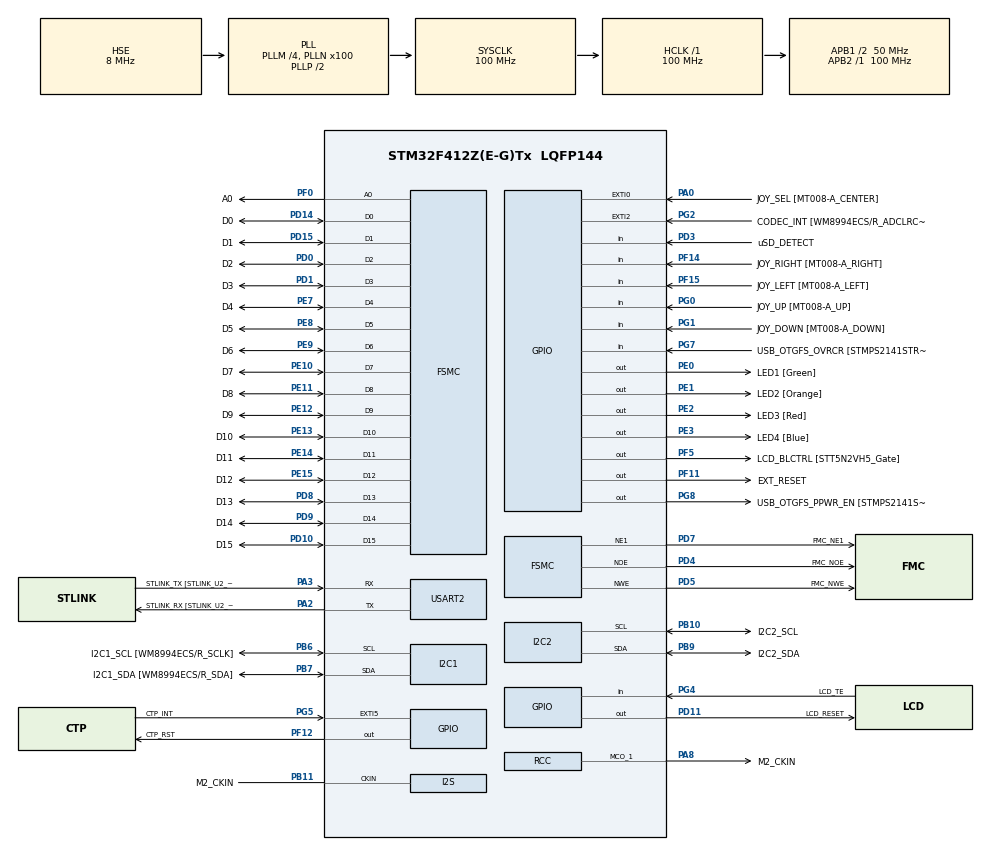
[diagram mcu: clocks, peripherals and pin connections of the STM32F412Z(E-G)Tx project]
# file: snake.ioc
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Mcu.Family=STM32F4
Mcu.Name=STM32F412Z(E-G)Tx
Mcu.Package=LQFP144
NVIC.PriorityGroup=NVIC_PRIORITYGROUP_4
NVIC.TIM6_IRQn=true\:0\:0\:false\:false\:true\:true\:true\:true
PA0.GPIO_Label=JOY_SEL [MT008-A_CENTER]
PA0.Signal=GPXTI0
PA10.GPIO_Label=USB_OTGFS_ID
PA10.Signal=USB_OTG_FS_ID
PA11.GPIO_Label=USB_OTGFS_DM
PA11.Signal=USB_OTG_FS_DM
PA13.GPIO_Label=SWDIO
PA13.Mode=Serial_Wire
PA13.Signal=SYS_JTMS-SWDIO
PA14.GPIO_Label=SWCLK
PA14.Mode=Serial_Wire
PA14.Signal=SYS_JTCK-SWCLK
PA2.GPIO_Label=STLINK_RX [STLINK_U2_RX]
PA2.Mode=Asynchronous
PA2.Signal=USART2_TX
PA3.GPIO_Label=STLINK_TX [STLINK_U2_TX]
PA3.Mode=Asynchronous
PA3.Signal=USART2_RX
PA4.GPIO_Label=CODEC_I2S3_WS [WM8994ECS/R_LRCLK1]
PA4.Signal=I2S3_WS
PA8.GPIO_Label=M2_CKIN
PA8.Mode=Clock-out-1
PA8.Signal=RCC_MCO_1
PA9.GPIO_Label=USB_OTGFS_VBUS
PA9.Signal=USB_OTG_FS_VBUS
PB1.GPIO_Label=DFSDM_DATIN0 [MP34DT01TR_DOUT]
PB1.Signal=S_DATAIN0DFSDM1
PB10.GPIO_Label=I2C2_SCL
PB10.GPIO_Pu=GPIO_PULLUP
PB10.Mode=I2C
PB10.Signal=I2C2_SCL
PB11.GPIO_Label=M2_CKIN
PB11.Mode=Audio_ClockIn
PB11.Signal=I2S_CKIN
PB12.GPIO_Label=CODEC_I2S3_SCK [WM8994ECS/R_BCLK1]
PB12.Signal=I2S3_CK
PB2.GPIO_Label=QSPI_CLK [N25Q128A13EF840F_C]
PB2.Signal=QUADSPI_CLK
PB3.GPIO_Label=SWO
PB3.Signal=SYS_JTDO-SWO
PB4.GPIO_Label=CODEC_I2S3ext_SD [WM8994ECS/R_ACDAT1]
PB4.Signal=I2S3_ext_SD
PB5.GPIO_Label=CODEC_I2S3_SD [WM8994ECS/R_DACDAT1]
PB5.Signal=I2S3_SD
PB6.GPIO_Label=I2C1_SCL [WM8994ECS/R_SCLK]
PB6.GPIO_Pu=GPIO_PULLUP
PB6.Mode=I2C
PB6.Signal=I2C1_SCL
PB7.GPIO_Label=I2C1_SDA [WM8994ECS/R_SDA]
PB7.GPIO_Pu=GPIO_PULLUP
PB7.Mode=I2C
PB7.Signal=I2C1_SDA
PB9.GPIO_Label=I2C2_SDA
PB9.GPIO_Pu=GPIO_PULLUP
PB9.Mode=I2C
PB9.Signal=I2C2_SDA
PC10.GPIO_Label=uSD_D2
PC10.Signal=SDIO_D2
PC11.GPIO_Label=uSD_D3
PC11.Signal=SDIO_D3
PC12.GPIO_Label=uSD_CLK
PC12.Signal=SDIO_CK
PC14-OSC32_IN.Mode=LSE-External-Oscillator
PC14-OSC32_IN.Signal=RCC_OSC32_IN
PC15-OSC32_OUT.Mode=LSE-External-Oscillator
PC15-OSC32_OUT.Signal=RCC_OSC32_OUT
PC2.GPIO_Label=DFSDM_CKOUT [MP34DT01TR_CLK]
PC2.Signal=S_CKOUTDFSDM1
PC7.GPIO_Label=CODEC_I2S3_MCK [WM8994ECS/R_MCLK1]
PC7.Signal=I2S3_MCK
PC8.GPIO_Label=uSD_D0
PC8.Signal=SDIO_D0
PC9.GPIO_Label=uSD_D1
PC9.Signal=SDIO_D1
PD0.GPIO_Label=D2
PD0.Signal=FSMC_D2_DA2
PD1.GPIO_Label=D3
PD1.Signal=FSMC_D3_DA3
PD10.GPIO_Label=D15
PD10.Signal=FSMC_D15_DA15
PD11.GPIO_Label=LCD_RESET
PD11.Signal=GPIO_Output
PD14.GPIO_Label=D0
PD14.Signal=FSMC_D0_DA0
PD15.GPIO_Label=D1
PD15.Signal=FSMC_D1_DA1
PD2.GPIO_Label=uSD_CMD
PD2.Signal=SDIO_CMD
PD3.GPIO_Label=uSD_DETECT
PD3.Signal=GPIO_Input
PD4.GPIO_Label=FMC_NOE
PD4.Signal=FSMC_NOE
PD5.GPIO_Label=FMC_NWE
PD5.Signal=FSMC_NWE
PD7.GPIO_Label=FMC_NE1
PD7.Mode=NorPsramChipSelect1_1
PD7.Signal=FSMC_NE1
PD8.GPIO_Label=D13
PD8.Signal=FSMC_D13_DA13
PD9.GPIO_Label=D14
PD9.Signal=FSMC_D14_DA14
PE0.GPIO_Label=LED1 [Green]
PE0.GPIO_ModeDefaultOutputPP=GPIO_MODE_OUTPUT_OD
PE0.Signal=GPIO_Output
PE1.GPIO_Label=LED2 [Orange]
PE1.GPIO_ModeDefaultOutputPP=GPIO_MODE_OUTPUT_OD
PE1.Signal=GPIO_Output
PE10.GPIO_Label=D7
PE10.Signal=FSMC_D7_DA7
PE11.GPIO_Label=D8
PE11.Signal=FSMC_D8_DA8
PE12.GPIO_Label=D9
PE12.Signal=FSMC_D9_DA9
PE13.GPIO_Label=D10
PE13.Signal=FSMC_D10_DA10
PE14.GPIO_Label=D11
PE14.Signal=FSMC_D11_DA11
PE15.GPIO_Label=D12
PE15.Signal=FSMC_D12_DA12
PE2.GPIO_Label=LED3 [Red]
PE2.GPIO_ModeDefaultOutputPP=GPIO_MODE_OUTPUT_OD
PE2.Signal=GPIO_Output
PE3.GPIO_Label=LED4 [Blue]
PE3.GPIO_ModeDefaultOutputPP=GPIO_MODE_OUTPUT_OD
PE3.Signal=GPIO_Output
PE4.GPIO_Label=DFSDM_DATIN3 [MP23DB01MM_DOUT]
PE4.Signal=S_DATAIN3DFSDM1
PE7.GPIO_Label=D4
PE7.Signal=FSMC_D4_DA4
PE8.GPIO_Label=D5
PE8.Signal=FSMC_D5_DA5
PE9.GPIO_Label=D6
PE9.Signal=FSMC_D6_DA6
PF0.GPIO_Label=A0
PF0.Signal=FSMC_A0
PF11.GPIO_Label=EXT_RESET
PF11.Signal=GPIO_Output
PF12.GPIO_Label=CTP_RST
PF12.Signal=GPIO_Output
PF14.GPIO_Label=JOY_RIGHT [MT008-A_RIGHT]
PF14.Signal=GPIO_Input
PF15.GPIO_Label=JOY_LEFT [MT008-A_LEFT]
PF15.Signal=GPIO_Input
PF5.GPIO_Label=LCD_BLCTRL [STT5N2VH5_Gate]
PF5.Signal=GPIO_Output
PF6.GPIO_Label=QSPI_BK1_IO3 [N25Q128A13EF840F_DQ3]
PF6.Signal=QUADSPI_BK1_IO3
PF7.GPIO_Label=QSPI_BK1_IO2 [N25Q128A13EF840F_DQ2]
PF7.Signal=QUADSPI_BK1_IO2
PF8.GPIO_Label=QSPI_BK1_IO0 [N25Q128A13EF840F_DQ0]
PF8.Signal=QUADSPI_BK1_IO0
PF9.GPIO_Label=QSPI_BK1_IO1 [N25Q128A13EF840F_DQ1]
PF9.Signal=QUADSPI_BK1_IO1
PG0.GPIO_Label=JOY_UP [MT008-A_UP]
PG0.Signal=GPIO_Input
PG1.GPIO_Label=JOY_DOWN [MT008-A_DOWN]
PG1.Signal=GPIO_Input
PG2.GPIO_Label=CODEC_INT [WM8994ECS/R_ADCLRCLK1/GPIO1]
PG2.Signal=GPXTI2
PG4.GPIO_Label=LCD_TE
PG4.Signal=GPIO_Input
PG5.GPIO_Label=CTP_INT
PG5.Signal=GPXTI5
PG6.GPIO_Label=QSPI_BK1_NCS [N25Q128A13EF840F_S]
PG6.Signal=QUADSPI_BK1_NCS
PG7.GPIO_Label=USB_OTGFS_OVRCR [STMPS2141STR_FAULT]
PG7.Signal=GPIO_Input
PG8.GPIO_Label=USB_OTGFS_PPWR_EN [STMPS2141STR_EN]
PG8.GPIO_ModeDefaultOutputPP=GPIO_MODE_OUTPUT_OD
PG8.PinState=GPIO_PIN_SET
PG8.Signal=GPIO_Output
PH0\ -\ OSC_IN.GPIO_Label=STLK_MCO
PH0\ -\ OSC_IN.Mode=HSE-External-Clock-Source
PH0\ -\ OSC_IN.Signal=RCC_OSC_IN
PH1\ -\ OSC_OUT.Mode=HSE-External-Clock-Source
PH1\ -\ OSC_OUT.Signal=RCC_OSC_OUT
ProjectManager.HeapSize=0x200
ProjectManager.StackSize=0x400
ProjectManager.TargetToolchain=STM32CubeIDE
RCC.48MHZClocksFreq_Value=48000000
RCC.AHBFreq_Value=100000000
RCC.APB1CLKDivider=RCC_HCLK_DIV2
RCC.APB1Freq_Value=50000000
RCC.APB1TimFreq_Value=100000000
RCC.APB2Freq_Value=100000000
RCC.APB2TimFreq_Value=100000000
RCC.CortexFreq_Value=100000000
RCC.HCLKFreq_Value=100000000
RCC.HSE_VALUE=8000000
RCC.HSI_VALUE=16000000
RCC.PLLI2SM=4
RCC.PLLI2SN=50
RCC.PLLM=4
RCC.PLLN=100
RCC.PLLQ=4
RCC.PLLSourceVirtual=RCC_PLLSOURCE_HSE
RCC.SYSCLKFreq_VALUE=100000000
RCC.SYSCLKSource=RCC_SYSCLKSOURCE_PLLCLK
RCC.USBFreq_Value=50000000
RCC.VCOOutputFreq_Value=200000000
SH.FSMC_A0.0=FSMC_A0,A0_1
SH.FSMC_D0_DA0.0=FSMC_D0,16b-d1
SH.FSMC_D10_DA10.0=FSMC_D10,16b-d1
SH.FSMC_D11_DA11.0=FSMC_D11,16b-d1
SH.FSMC_D12_DA12.0=FSMC_D12,16b-d1
SH.FSMC_D13_DA13.0=FSMC_D13,16b-d1
SH.FSMC_D14_DA14.0=FSMC_D14,16b-d1
SH.FSMC_D15_DA15.0=FSMC_D15,16b-d1
SH.FSMC_D1_DA1.0=FSMC_D1,16b-d1
SH.FSMC_D2_DA2.0=FSMC_D2,16b-d1
SH.FSMC_D3_DA3.0=FSMC_D3,16b-d1
SH.FSMC_D4_DA4.0=FSMC_D4,16b-d1
SH.FSMC_D5_DA5.0=FSMC_D5,16b-d1
SH.FSMC_D6_DA6.0=FSMC_D6,16b-d1
SH.FSMC_D7_DA7.0=FSMC_D7,16b-d1
SH.FSMC_D8_DA8.0=FSMC_D8,16b-d1
SH.FSMC_D9_DA9.0=FSMC_D9,16b-d1
SH.FSMC_NOE.0=FSMC_NOE,Lcd1
SH.FSMC_NWE.0=FSMC_NWE,Lcd1
SH.S_CKOUTDFSDM1.0=DFSDM1_CKOUT
SH.S_DATAIN0DFSDM1.0=DFSDM1_DATIN0
SH.S_DATAIN3DFSDM1.0=DFSDM1_DATIN3
TIM6.AutoReloadPreload=TIM_AUTORELOAD_PRELOAD_ENABLE
TIM6.Period=9
TIM6.Prescaler=9999
TIM7.Prescaler=999
USART2.VirtualMode=VM_ASYNC
VP_RNG_VS_RNG.Mode=RNG_Activate
VP_TIM6_VS_ClockSourceINT.Mode=Enable_Timer
VP_TIM7_VS_ClockSourceINT.Mode=Enable_Timer
board=STM32F412G-DISCO

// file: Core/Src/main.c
/* USER CODE BEGIN Header */
/**
  ******************************************************************************
  * @file           : main.c
  * @brief          : Main program body
  ******************************************************************************
  * @attention
  *
  * Copyright (c) 2022 STMicroelectronics.
  * All rights reserved.
  *
  * This software is licensed under terms that can be found in the LICENSE file
  * in the root directory of this software component.
  * If no LICENSE file comes with this software, it is provided AS-IS.
  *
  ******************************************************************************
  */
/* USER CODE END Header */
#include "main.h"

/* USER CODE BEGIN Includes */
#include "menu.h"
/* USER CODE END Includes */

I2C_HandleTypeDef hi2c1;
I2C_HandleTypeDef hi2c2;

RNG_HandleTypeDef hrng;

TIM_HandleTypeDef htim6;
TIM_HandleTypeDef htim7;

UART_HandleTypeDef huart2;

SRAM_HandleTypeDef hsram1;

/* USER CODE BEGIN PV */
volatile bool timerFlag = false;
/* USER CODE END PV */

void SystemClock_Config(void);
static void MX_GPIO_Init(void);
static void MX_FSMC_Init(void);
static void MX_I2C1_Init(void);
static void MX_I2C2_Init(void);
static void MX_USART2_UART_Init(void);
static void MX_RNG_Init(void);
static void MX_TIM6_Init(void);
static void MX_TIM7_Init(void);

int main(void)
{

  /* MCU Configuration--------------------------------------------------------*/

  /* Reset of all peripherals, Initializes the Flash interface and the Systick. */
  HAL_Init();

  /* Configure the system clock */
  SystemClock_Config();

  /* Initialize all configured peripherals */
  MX_GPIO_Init();
  MX_FSMC_Init();
  MX_I2C1_Init();
  MX_I2C2_Init();
  MX_USART2_UART_Init();
  MX_RNG_Init();
  MX_TIM6_Init();
  MX_TIM7_Init();
  /* USER CODE BEGIN 2 */
  BSP_LCD_Init();
  HAL_TIM_Base_Start_IT(&htim6);
  HAL_TIM_Base_Start(&htim7);
  /* USER CODE END 2 */

  /* Infinite loop */
  /* USER CODE BEGIN WHILE */

  while (true)
  {
	  DisplayMenu();

    /* USER CODE END WHILE */

  }
}

void SystemClock_Config(void)
{
  RCC_OscInitTypeDef RCC_OscInitStruct = {0};
  RCC_ClkInitTypeDef RCC_ClkInitStruct = {0};

  /** Configure the main internal regulator output voltage
  */
  __HAL_RCC_PWR_CLK_ENABLE();
  __HAL_PWR_VOLTAGESCALING_CONFIG(PWR_REGULATOR_VOLTAGE_SCALE1);

  /** Initializes the RCC Oscillators according to the specified parameters
  * in the RCC_OscInitTypeDef structure.
  */
  RCC_OscInitStruct.OscillatorType = RCC_OSCILLATORTYPE_HSI|RCC_OSCILLATORTYPE_HSE;
  RCC_OscInitStruct.HSEState = RCC_HSE_BYPASS;
  RCC_OscInitStruct.HSIState = RCC_HSI_ON;
  RCC_OscInitStruct.HSICalibrationValue = RCC_HSICALIBRATION_DEFAULT;
  RCC_OscInitStruct.PLL.PLLState = RCC_PLL_ON;
  RCC_OscInitStruct.PLL.PLLSource = RCC_PLLSOURCE_HSE;
  RCC_OscInitStruct.PLL.PLLM = 4;
  RCC_OscInitStruct.PLL.PLLN = 100;
  RCC_OscInitStruct.PLL.PLLP = RCC_PLLP_DIV2;
  RCC_OscInitStruct.PLL.PLLQ = 4;
  RCC_OscInitStruct.PLL.PLLR = 2;
  if (HAL_RCC_OscConfig(&RCC_OscInitStruct) != HAL_OK)
  {
    Error_Handler();
  }

  /** Initializes the CPU, AHB and APB buses clocks
  */
  RCC_ClkInitStruct.ClockType = RCC_CLOCKTYPE_HCLK|RCC_CLOCKTYPE_SYSCLK
                              |RCC_CLOCKTYPE_PCLK1|RCC_CLOCKTYPE_PCLK2;
  RCC_ClkInitStruct.SYSCLKSource = RCC_SYSCLKSOURCE_PLLCLK;
  RCC_ClkInitStruct.AHBCLKDivider = RCC_SYSCLK_DIV1;
  RCC_ClkInitStruct.APB1CLKDivider = RCC_HCLK_DIV2;
  RCC_ClkInitStruct.APB2CLKDivider = RCC_HCLK_DIV1;

  if (HAL_RCC_ClockConfig(&RCC_ClkInitStruct, FLASH_LATENCY_3) != HAL_OK)
  {
    Error_Handler();
  }
  HAL_RCC_MCOConfig(RCC_MCO1, RCC_MCO1SOURCE_HSI, RCC_MCODIV_1);
}

static void MX_I2C1_Init(void)
{

  hi2c1.Instance = I2C1;
  hi2c1.Init.ClockSpeed = 100000;
  hi2c1.Init.DutyCycle = I2C_DUTYCYCLE_2;
  hi2c1.Init.OwnAddress1 = 0;
  hi2c1.Init.AddressingMode = I2C_ADDRESSINGMODE_7BIT;
  hi2c1.Init.DualAddressMode = I2C_DUALADDRESS_DISABLE;
  hi2c1.Init.OwnAddress2 = 0;
  hi2c1.Init.GeneralCallMode = I2C_GENERALCALL_DISABLE;
  hi2c1.Init.NoStretchMode = I2C_NOSTRETCH_DISABLE;
  if (HAL_I2C_Init(&hi2c1) != HAL_OK)
  {
    Error_Handler();
  }

}

static void MX_I2C2_Init(void)
{

  hi2c2.Instance = I2C2;
  hi2c2.Init.ClockSpeed = 100000;
  hi2c2.Init.DutyCycle = I2C_DUTYCYCLE_2;
  hi2c2.Init.OwnAddress1 = 0;
  hi2c2.Init.AddressingMode = I2C_ADDRESSINGMODE_7BIT;
  hi2c2.Init.DualAddressMode = I2C_DUALADDRESS_DISABLE;
  hi2c2.Init.OwnAddress2 = 0;
  hi2c2.Init.GeneralCallMode = I2C_GENERALCALL_DISABLE;
  hi2c2.Init.NoStretchMode = I2C_NOSTRETCH_DISABLE;
  if (HAL_I2C_Init(&hi2c2) != HAL_OK)
  {
    Error_Handler();
  }

}

static void MX_RNG_Init(void)
{

  hrng.Instance = RNG;
  if (HAL_RNG_Init(&hrng) != HAL_OK)
  {
    Error_Handler();
  }

}

static void MX_TIM6_Init(void)
{

  TIM_MasterConfigTypeDef sMasterConfig = {0};

  htim6.Instance = TIM6;
  htim6.Init.Prescaler = 9999;
  htim6.Init.CounterMode = TIM_COUNTERMODE_UP;
  htim6.Init.Period = 9;
  htim6.Init.AutoReloadPreload = TIM_AUTORELOAD_PRELOAD_ENABLE;
  if (HAL_TIM_Base_Init(&htim6) != HAL_OK)
  {
    Error_Handler();
  }
  sMasterConfig.MasterOutputTrigger = TIM_TRGO_RESET;
  sMasterConfig.MasterSlaveMode = TIM_MASTERSLAVEMODE_DISABLE;
  if (HAL_TIMEx_MasterConfigSynchronization(&htim6, &sMasterConfig) != HAL_OK)
  {
    Error_Handler();
  }

}

static void MX_TIM7_Init(void)
{

  htim7.Instance = TIM7;
  htim7.Init.Prescaler = 999;
  htim7.Init.CounterMode = TIM_COUNTERMODE_UP;
  htim7.Init.Period = 65535;
  htim7.Init.AutoReloadPreload = TIM_AUTORELOAD_PRELOAD_DISABLE;
  if (HAL_TIM_Base_Init(&htim7) != HAL_OK)
  {
    Error_Handler();
  }

}

static void MX_USART2_UART_Init(void)
{

  huart2.Instance = USART2;
  huart2.Init.BaudRate = 115200;
  huart2.Init.WordLength = UART_WORDLENGTH_8B;
  huart2.Init.StopBits = UART_STOPBITS_1;
  huart2.Init.Parity = UART_PARITY_NONE;
  huart2.Init.Mode = UART_MODE_TX_RX;
  huart2.Init.HwFlowCtl = UART_HWCONTROL_NONE;
  huart2.Init.OverSampling = UART_OVERSAMPLING_16;
  if (HAL_UART_Init(&huart2) != HAL_OK)
  {
    Error_Handler();
  }

}

static void MX_GPIO_Init(void)
{
  GPIO_InitTypeDef GPIO_InitStruct = {0};

  /* GPIO Ports Clock Enable */
  __HAL_RCC_GPIOE_CLK_ENABLE();
  __HAL_RCC_GPIOC_CLK_ENABLE();
  __HAL_RCC_GPIOF_CLK_ENABLE();
  __HAL_RCC_GPIOH_CLK_ENABLE();
  __HAL_RCC_GPIOA_CLK_ENABLE();
  __HAL_RCC_GPIOB_CLK_ENABLE();
  __HAL_RCC_GPIOG_CLK_ENABLE();
  __HAL_RCC_GPIOD_CLK_ENABLE();

  /*Configure GPIO pin Output Level */
  HAL_GPIO_WritePin(GPIOE, LED3_Pin|LED4_Pin|LED1_Pin|LED2_Pin, GPIO_PIN_RESET);

  /*Configure GPIO pin Output Level */
  HAL_GPIO_WritePin(GPIOF, LCD_BLCTRL_Pin|EXT_RESET_Pin|CTP_RST_Pin, GPIO_PIN_RESET);

  /*Configure GPIO pin Output Level */
  HAL_GPIO_WritePin(LCD_RESET_GPIO_Port, LCD_RESET_Pin, GPIO_PIN_RESET);

  /*Configure GPIO pin Output Level */
  HAL_GPIO_WritePin(USB_OTGFS_PPWR_EN_GPIO_Port, USB_OTGFS_PPWR_EN_Pin, GPIO_PIN_SET);

  /*Configure GPIO pins : LED3_Pin LED4_Pin LED1_Pin LED2_Pin */
  GPIO_InitStruct.Pin = LED3_Pin|LED4_Pin|LED1_Pin|LED2_Pin;
  GPIO_InitStruct.Mode = GPIO_MODE_OUTPUT_OD;
  GPIO_InitStruct.Pull = GPIO_NOPULL;
  GPIO_InitStruct.Speed = GPIO_SPEED_FREQ_LOW;
  HAL_GPIO_Init(GPIOE, &GPIO_InitStruct);

  /*Configure GPIO pin : DFSDM_DATIN3_Pin */
  GPIO_InitStruct.Pin = DFSDM_DATIN3_Pin;
  GPIO_InitStruct.Mode = GPIO_MODE_AF_PP;
  GPIO_InitStruct.Pull = GPIO_NOPULL;
  GPIO_InitStruct.Speed = GPIO_SPEED_FREQ_LOW;
  GPIO_InitStruct.Alternate = GPIO_AF8_DFSDM1;
  HAL_GPIO_Init(DFSDM_DATIN3_GPIO_Port, &GPIO_InitStruct);

  /*Configure GPIO pins : LCD_BLCTRL_Pin EXT_RESET_Pin CTP_RST_Pin */
  GPIO_InitStruct.Pin = LCD_BLCTRL_Pin|EXT_RESET_Pin|CTP_RST_Pin;
  GPIO_InitStruct.Mode = GPIO_MODE_OUTPUT_PP;
  GPIO_InitStruct.Pull = GPIO_NOPULL;
  GPIO_InitStruct.Speed = GPIO_SPEED_FREQ_LOW;
  HAL_GPIO_Init(GPIOF, &GPIO_InitStruct);

  /*Configure GPIO pins : QSPI_BK1_IO3_Pin QSPI_BK1_IO2_Pin */
  GPIO_InitStruct.Pin = QSPI_BK1_IO3_Pin|QSPI_BK1_IO2_Pin;
  GPIO_InitStruct.Mode = GPIO_MODE_AF_PP;
  GPIO_InitStruct.Pull = GPIO_NOPULL;
  GPIO_InitStruct.Speed = GPIO_SPEED_FREQ_VERY_HIGH;
  GPIO_InitStruct.Alternate = GPIO_AF9_QSPI;
  HAL_GPIO_Init(GPIOF, &GPIO_InitStruct);

  /*Configure GPIO pins : QSPI_BK1_IO0_Pin QSPI_BK1_IO1_Pin */
  GPIO_InitStruct.Pin = QSPI_BK1_IO0_Pin|QSPI_BK1_IO1_Pin;
  GPIO_InitStruct.Mode = GPIO_MODE_AF_PP;
  GPIO_InitStruct.Pull = GPIO_NOPULL;
  GPIO_InitStruct.Speed = GPIO_SPEED_FREQ_VERY_HIGH;
  GPIO_InitStruct.Alternate = GPIO_AF10_OTG_FS;
  HAL_GPIO_Init(GPIOF, &GPIO_InitStruct);

  /*Configure GPIO pin : DFSDM_CKOUT_Pin */
  GPIO_InitStruct.Pin = DFSDM_CKOUT_Pin;
  GPIO_InitStruct.Mode = GPIO_MODE_AF_PP;
  GPIO_InitStruct.Pull = GPIO_NOPULL;
  GPIO_InitStruct.Speed = GPIO_SPEED_FREQ_LOW;
  GPIO_InitStruct.Alternate = GPIO_AF8_DFSDM1;
  HAL_GPIO_Init(DFSDM_CKOUT_GPIO_Port, &GPIO_InitStruct);

  /*Configure GPIO pin : JOY_SEL_Pin */
  GPIO_InitStruct.Pin = JOY_SEL_Pin;
  GPIO_InitStruct.Mode = GPIO_MODE_IT_RISING;
  GPIO_InitStruct.Pull = GPIO_NOPULL;
  HAL_GPIO_Init(JOY_SEL_GPIO_Port, &GPIO_InitStruct);

  /*Configure GPIO pin : CODEC_I2S3_WS_Pin */
  GPIO_InitStruct.Pin = CODEC_I2S3_WS_Pin;
  GPIO_InitStruct.Mode = GPIO_MODE_AF_PP;
  GPIO_InitStruct.Pull = GPIO_NOPULL;
  GPIO_InitStruct.Speed = GPIO_SPEED_FREQ_LOW;
  GPIO_InitStruct.Alternate = GPIO_AF6_SPI3;
  HAL_GPIO_Init(CODEC_I2S3_WS_GPIO_Port, &GPIO_InitStruct);

  /*Configure GPIO pin : DFSDM_DATIN0_Pin */
  GPIO_InitStruct.Pin = DFSDM_DATIN0_Pin;
  GPIO_InitStruct.Mode = GPIO_MODE_AF_PP;
  GPIO_InitStruct.Pull = GPIO_NOPULL;
  GPIO_InitStruct.Speed = GPIO_SPEED_FREQ_LOW;
  GPIO_InitStruct.Alternate = GPIO_AF8_DFSDM1;
  HAL_GPIO_Init(DFSDM_DATIN0_GPIO_Port, &GPIO_InitStruct);

  /*Configure GPIO pin : QSPI_CLK_Pin */
  GPIO_InitStruct.Pin = QSPI_CLK_Pin;
  GPIO_InitStruct.Mode = GPIO_MODE_AF_PP;
  GPIO_InitStruct.Pull = GPIO_NOPULL;
  GPIO_InitStruct.Speed = GPIO_SPEED_FREQ_VERY_HIGH;
  GPIO_InitStruct.Alternate = GPIO_AF9_QSPI;
  HAL_GPIO_Init(QSPI_CLK_GPIO_Port, &GPIO_InitStruct);

  /*Configure GPIO pins : JOY_RIGHT_Pin JOY_LEFT_Pin */
  GPIO_InitStruct.Pin = JOY_RIGHT_Pin|JOY_LEFT_Pin;
  GPIO_InitStruct.Mode = GPIO_MODE_INPUT;
  GPIO_InitStruct.Pull = GPIO_NOPULL;
  HAL_GPIO_Init(GPIOF, &GPIO_InitStruct);

  /*Configure GPIO pins : JOY_UP_Pin JOY_DOWN_Pin LCD_TE_Pin USB_OTGFS_OVRCR_Pin */
  GPIO_InitStruct.Pin = JOY_UP_Pin|JOY_DOWN_Pin|LCD_TE_Pin|USB_OTGFS_OVRCR_Pin;
  GPIO_InitStruct.Mode = GPIO_MODE_INPUT;
  GPIO_InitStruct.Pull = GPIO_NOPULL;
  HAL_GPIO_Init(GPIOG, &GPIO_InitStruct);

  /*Configure GPIO pin : M2_CKIN_Pin */
  GPIO_InitStruct.Pin = M2_CKIN_Pin;
  GPIO_InitStruct.Mode = GPIO_MODE_AF_PP;
  GPIO_InitStruct.Pull = GPIO_NOPULL;
  GPIO_InitStruct.Speed = GPIO_SPEED_FREQ_LOW;
  GPIO_InitStruct.Alternate = GPIO_AF5_SPI1;
  HAL_GPIO_Init(M2_CKIN_GPIO_Port, &GPIO_InitStruct);

  /*Configure GPIO pins : CODEC_I2S3_SCK_Pin CODEC_I2S3ext_SD_Pin */
  GPIO_InitStruct.Pin = CODEC_I2S3_SCK_Pin|CODEC_I2S3ext_SD_Pin;
  GPIO_InitStruct.Mode = GPIO_MODE_AF_PP;
  GPIO_InitStruct.Pull = GPIO_NOPULL;
  GPIO_InitStruct.Speed = GPIO_SPEED_FREQ_LOW;
  GPIO_InitStruct.Alternate = GPIO_AF7_SPI3;
  HAL_GPIO_Init(GPIOB, &GPIO_InitStruct);

  /*Configure GPIO pin : LCD_RESET_Pin */
  GPIO_InitStruct.Pin = LCD_RESET_Pin;
  GPIO_InitStruct.Mode = GPIO_MODE_OUTPUT_PP;
  GPIO_InitStruct.Pull = GPIO_NOPULL;
  GPIO_InitStruct.Speed = GPIO_SPEED_FREQ_LOW;
  HAL_GPIO_Init(LCD_RESET_GPIO_Port, &GPIO_InitStruct);

  /*Configure GPIO pins : CODEC_INT_Pin CTP_INT_Pin */
  GPIO_InitStruct.Pin = CODEC_INT_Pin|CTP_INT_Pin;
  GPIO_InitStruct.Mode = GPIO_MODE_IT_RISING;
  GPIO_InitStruct.Pull = GPIO_NOPULL;
  HAL_GPIO_Init(GPIOG, &GPIO_InitStruct);

  /*Configure GPIO pin : QSPI_BK1_NCS_Pin */
  GPIO_InitStruct.Pin = QSPI_BK1_NCS_Pin;
  GPIO_InitStruct.Mode = GPIO_MODE_AF_PP;
  GPIO_InitStruct.Pull = GPIO_NOPULL;
  GPIO_InitStruct.Speed = GPIO_SPEED_FREQ_VERY_HIGH;
  GPIO_InitStruct.Alternate = GPIO_AF10_OTG_FS;
  HAL_GPIO_Init(QSPI_BK1_NCS_GPIO_Port, &GPIO_InitStruct);

  /*Configure GPIO pin : USB_OTGFS_PPWR_EN_Pin */
  GPIO_InitStruct.Pin = USB_OTGFS_PPWR_EN_Pin;
  GPIO_InitStruct.Mode = GPIO_MODE_OUTPUT_OD;
  GPIO_InitStruct.Pull = GPIO_NOPULL;
  GPIO_InitStruct.Speed = GPIO_SPEED_FREQ_LOW;
  HAL_GPIO_Init(USB_OTGFS_PPWR_EN_GPIO_Port, &GPIO_InitStruct);

  /*Configure GPIO pin : CODEC_I2S3_MCK_Pin */
  GPIO_InitStruct.Pin = CODEC_I2S3_MCK_Pin;
  GPIO_InitStruct.Mode = GPIO_MODE_AF_PP;
  GPIO_InitStruct.Pull = GPIO_NOPULL;
  GPIO_InitStruct.Speed = GPIO_SPEED_FREQ_LOW;
  GPIO_InitStruct.Alternate = GPIO_AF6_SPI3;
  HAL_GPIO_Init(CODEC_I2S3_MCK_GPIO_Port, &GPIO_InitStruct);

  /*Configure GPIO pins : uSD_D0_Pin uSD_D1_Pin uSD_D2_Pin uSD_D3_Pin
                           uSD_CLK_Pin */
  GPIO_InitStruct.Pin = uSD_D0_Pin|uSD_D1_Pin|uSD_D2_Pin|uSD_D3_Pin
                          |uSD_CLK_Pin;
  GPIO_InitStruct.Mode = GPIO_MODE_AF_PP;
  GPIO_InitStruct.Pull = GPIO_NOPULL;
  GPIO_InitStruct.Speed = GPIO_SPEED_FREQ_VERY_HIGH;
  GPIO_InitStruct.Alternate = GPIO_AF12_SDIO;
  HAL_GPIO_Init(GPIOC, &GPIO_InitStruct);

  /*Configure GPIO pin : M2_CKINA8_Pin */
  GPIO_InitStruct.Pin = M2_CKINA8_Pin;
  GPIO_InitStruct.Mode = GPIO_MODE_AF_PP;
  GPIO_InitStruct.Pull = GPIO_NOPULL;
  GPIO_InitStruct.Speed = GPIO_SPEED_FREQ_LOW;
  GPIO_InitStruct.Alternate = GPIO_AF0_MCO;
  HAL_GPIO_Init(M2_CKINA8_GPIO_Port, &GPIO_InitStruct);

  /*Configure GPIO pins : USB_OTGFS_ID_Pin USB_OTGFS_DM_Pin */
  GPIO_InitStruct.Pin = USB_OTGFS_ID_Pin|USB_OTGFS_DM_Pin;
  GPIO_InitStruct.Mode = GPIO_MODE_AF_PP;
  GPIO_InitStruct.Pull = GPIO_NOPULL;
  GPIO_InitStruct.Speed = GPIO_SPEED_FREQ_VERY_HIGH;
  GPIO_InitStruct.Alternate = GPIO_AF10_OTG_FS;
  HAL_GPIO_Init(GPIOA, &GPIO_InitStruct);

  /*Configure GPIO pin : uSD_CMD_Pin */
  GPIO_InitStruct.Pin = uSD_CMD_Pin;
  GPIO_InitStruct.Mode = GPIO_MODE_AF_PP;
  GPIO_InitStruct.Pull = GPIO_NOPULL;
  GPIO_InitStruct.Speed = GPIO_SPEED_FREQ_VERY_HIGH;
  GPIO_InitStruct.Alternate = GPIO_AF12_SDIO;
  HAL_GPIO_Init(uSD_CMD_GPIO_Port, &GPIO_InitStruct);

  /*Configure GPIO pin : uSD_DETECT_Pin */
  GPIO_InitStruct.Pin = uSD_DETECT_Pin;
  GPIO_InitStruct.Mode = GPIO_MODE_INPUT;
  GPIO_InitStruct.Pull = GPIO_NOPULL;
  HAL_GPIO_Init(uSD_DETECT_GPIO_Port, &GPIO_InitStruct);

  /*Configure GPIO pin : CODEC_I2S3_SD_Pin */
  GPIO_InitStruct.Pin = CODEC_I2S3_SD_Pin;
  GPIO_InitStruct.Mode = GPIO_MODE_AF_PP;
  GPIO_InitStruct.Pull = GPIO_NOPULL;
  GPIO_InitStruct.Speed = GPIO_SPEED_FREQ_LOW;
  GPIO_InitStruct.Alternate = GPIO_AF6_SPI3;
  HAL_GPIO_Init(CODEC_I2S3_SD_GPIO_Port, &GPIO_InitStruct);

}

/* FSMC initialization function */
static void MX_FSMC_Init(void)
{

  FSMC_NORSRAM_TimingTypeDef Timing = {0};

  /** Perform the SRAM1 memory initialization sequence
  */
  hsram1.Instance = FSMC_NORSRAM_DEVICE;
  hsram1.Extended = FSMC_NORSRAM_EXTENDED_DEVICE;
  /* hsram1.Init */
  hsram1.Init.NSBank = FSMC_NORSRAM_BANK1;
  hsram1.Init.DataAddressMux = FSMC_DATA_ADDRESS_MUX_DISABLE;
  hsram1.Init.MemoryType = FSMC_MEMORY_TYPE_SRAM;
  hsram1.Init.MemoryDataWidth = FSMC_NORSRAM_MEM_BUS_WIDTH_16;
  hsram1.Init.BurstAccessMode = FSMC_BURST_ACCESS_MODE_DISABLE;
  hsram1.Init.WaitSignalPolarity = FSMC_WAIT_SIGNAL_POLARITY_LOW;
  hsram1.Init.WaitSignalActive = FSMC_WAIT_TIMING_BEFORE_WS;
  hsram1.Init.WriteOperation = FSMC_WRITE_OPERATION_ENABLE;
  hsram1.Init.WaitSignal = FSMC_WAIT_SIGNAL_DISABLE;
  hsram1.Init.ExtendedMode = FSMC_EXTENDED_MODE_DISABLE;
  hsram1.Init.AsynchronousWait = FSMC_ASYNCHRONOUS_WAIT_DISABLE;
  hsram1.Init.WriteBurst = FSMC_WRITE_BURST_DISABLE;
  hsram1.Init.ContinuousClock = FSMC_CONTINUOUS_CLOCK_SYNC_ONLY;
  hsram1.Init.WriteFifo = FSMC_WRITE_FIFO_ENABLE;
  hsram1.Init.PageSize = FSMC_PAGE_SIZE_NONE;
  /* Timing */
  Timing.AddressSetupTime = 15;
  Timing.AddressHoldTime = 15;
  Timing.DataSetupTime = 255;
  Timing.BusTurnAroundDuration = 15;
  Timing.CLKDivision = 16;
  Timing.DataLatency = 17;
  Timing.AccessMode = FSMC_ACCESS_MODE_A;
  /* ExtTiming */

  if (HAL_SRAM_Init(&hsram1, &Timing, NULL) != HAL_OK)
  {
    Error_Handler( );
  }

}

void Error_Handler(void)
{
  __disable_irq();
  while (1)
  {
  }
}
